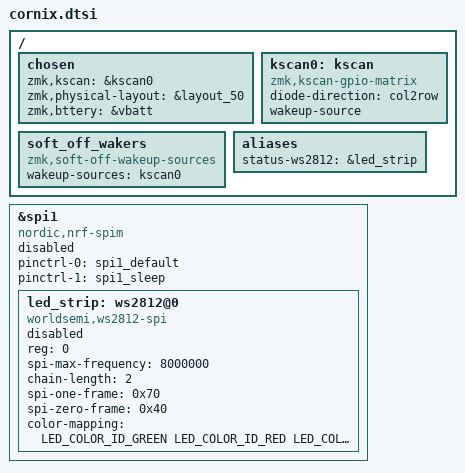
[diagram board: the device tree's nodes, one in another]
/*
 * Copyright (c) 2020 Pete Johanson
 *
 * SPDX-License-Identifier: MIT
 */
#include <nordic/nrf52840_qiaa.dtsi>
#include <dt-bindings/led/led.h>
#include "cornix-pinctrl.dtsi"
#include "cornix-layouts.dtsi"
#include "cornix_sensors.dtsi"
#include "nrf_e73.dtsi"
/ {
    chosen {
        zmk,kscan = &kscan0;
		zmk,physical-layout = &layout_50;
    };


    kscan0: kscan {
        compatible = "zmk,kscan-gpio-matrix";
        diode-direction = "col2row";
        wakeup-source;
    };

};

&spi1 {
    status = "disabled";

    compatible = "nordic,nrf-spim";


        pinctrl-0 = <&spi1_default>;
        pinctrl-1 = <&spi1_sleep>;
        pinctrl-names = "default", "sleep";

    led_strip: ws2812@0 {
        status = "disabled";
        compatible = "worldsemi,ws2812-spi";

        /* SPI */
        reg = <0>; /* ignored, but necessary for SPI bindings */
        spi-max-frequency = <8000000>;  // 8MHz

        /* WS2812 */
        chain-length = <2>; 
        spi-one-frame = <0x70>;
        spi-zero-frame = <0x40>;
        color-mapping = <LED_COLOR_ID_GREEN LED_COLOR_ID_RED LED_COLOR_ID_BLUE>;
    };
};



/ {
    // rgb_underglow: rgb_underglow {
    //     status = "okay";
    //     compatible = "zmk,rgb-underglow";
    //     label = "RGB";
    //     chain-length = <2>;
    //     brightness = <60>;
    //     effect = "breathing";
    // };
    soft_off_wakers {
        compatible = "zmk,soft-off-wakeup-sources";
        wakeup-sources = <&kscan0>;
    };

    aliases {
        status-ws2812 = &led_strip;
    };
    chosen {
        zmk,bttery = &vbatt;
		// widget,rgb = &led_strip;
		// zmk,underglow = &led_strip;
    };

};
